# cslr_mcbsp register map
Vendor: Texas Instruments
Peripheral module from a debugger description file (folder TCI6484_C6457).
Registers are 32-bit, read-write, reset 0x0 unless marked. A register's access mark holds for its fields unless they carry their own. Offsets are as the file gives them; lines under a group give offsets from that group; [hi:lo] are bit positions; {n}, {i} and the like mark numbered series; 'fields as' and 'values as' point back to an identical list; <NAME> marks a mode.

## MCBSP
0x00 DRR ro — Data Receive Register
  [31:0] DR — Receive data
0x04 DXR ro — Data Transmit Register
  [31:0] DX — Transmit data
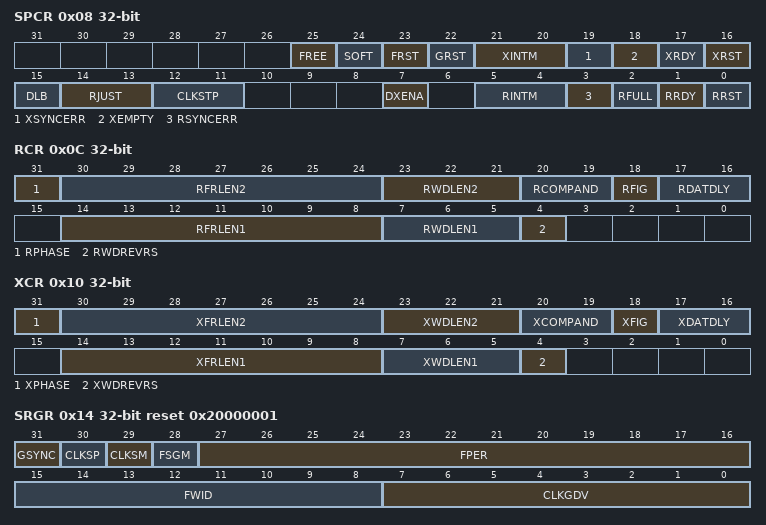
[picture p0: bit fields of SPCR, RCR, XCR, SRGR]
0x08 SPCR access not given — Serial Port Control Register
  [25] FREE rw — McBSP emulation mode bit (free mode)
    0=DISABLE; 1=ENABLE
  [24] SOFT rw — McBSP emulation mode bit (soft mode)
    0=DISABLE; 1=ENABLE
  [23] FRST rw — Frame-sync logic reset bit (negative polarity)
    0=RESET; 1=LOAD
  [22] GRST rw — Sample rate generator reset bit (negative polarity)
    0=RESET; 1=OUT_RST
  [21:20] XINTM rw — Transmit interrupt mode bits
  [19] XSYNCERR rw — Transmit frame-sync error bit (Caution: if XINTM = 11b, writing a 1 to XSYNCERR triggers a transmit interrupt just as if a transmit frame-sync error occurred)
    0=NO_ERR; 1=ERR
  [18] XEMPTY ro — Transmitter empty bit (negative polarity)
    0=EMPTY; 1=NOTEMPTY
  [17] XRDY ro — Transmitter ready bit
    0=NOTREADY; 1=READY
  [16] XRST rw — Transmitter reset bit (negative polarity)
    0=DISABLE; 1=ENABLE
  [15] DLB rw — Digital loopback mode bit
    0=DISABLE; 1=ENABLE
  [14:13] RJUST rw — Receive sign-extension and justification mode bits
  [12:11] CLKSTP rw — Clock stop mode bits
  [7] DXENA rw — DX delay enabler mode bit
    0=OFF; 1=ON
  [5:4] RINTM rw — Receive interrupt mode bits
  [3] RSYNCERR rw — Receive frame-sync error bit (Caution: If RINTM = 11b, writing a 1 to RSYNCERR triggers a receive interrupt just as if a receive frame-sync error occurred)
    0=NO_ERR; 1=ERR
  [2] RFULL ro — Receiver full bit
    0=NOT_FULL; 1=FULL
  [1] RRDY ro — Receiver ready bit
    0=NOTREADY; 1=READY
  [0] RRST rw — Receiver reset bit (negative polarity)
    0=DISABLE; 1=ENABLE
0x0C RCR access not given — Receive Control Register
  [31] RPHASE rw — Receive phase number bit
    0=SINGLEPHASE; 1=DUALPHASE
  [30:24] RFRLEN2 rw — Receive frame length 2
  [23:21] RWDLEN2 rw — Receive word length 2. Word length 11x b Reserved
  [20:19] RCOMPAND rw — Receive companding mode bits
  [18] RFIG rw — Receive frame-sync ignore bit
    0=RESTART; 1=IGNORE
  [17:16] RDATDLY rw — Receive data delay bits
  [14:8] RFRLEN1 rw — Receive frame length 1
  [7:5] RWDLEN1 rw — Receive word length 1.Word length 11x b Reserved
  [4] RWDREVRS rw — Receive 32-bit reversal feature 0: 32-bit reversal disabled 1: 32-bit reversal enabled. 32-bit data is received LSB first. RWDLEN should be set for 32-bit operation; else operation is undefined
    0=DISABLE; 1=ENABLE
0x10 XCR access not given — Transmit Control Register
  [31] XPHASE rw — Transmit phase number bit
    0=SINGLEPHASE; 1=DUALPHASE
  [30:24] XFRLEN2 rw — Transmit frame length 2
  [23:21] XWDLEN2 rw — Transmit word length 2. Word length 11x b Reserved
  [20:19] XCOMPAND rw — Transmit companding mode bits
  [18] XFIG rw — Transmit frame-sync ignore bit
    0=RESTART; 1=IGNORE
  [17:16] XDATDLY rw — Transmit data delay bits
    0=0_BIT; 1=1_BIT; 2=2_BIT
  [14:8] XFRLEN1 rw — Transmit frame length 1
  [7:5] XWDLEN1 rw — Transmit word length 1.Word length 11x b Reserved
  [4] XWDREVRS rw — Transmit 32-bit reversal feature 0: 32-bit reversal disabled 1: 32-bit reversal enabled. 32-bit data is transmitted LSB first. RWDLEN should be set for 32-bit operation; else operation is undefined
    0=DISABLE; 1=ENABLE
0x14 SRGR reset 0x20000001 — Sample Rate Generator Register
  [31] GSYNC — Clock synchronization mode bit for CLKG
    0=FREE_RUNNING; 1=RUNNING
  [30] CLKSP — CLKS pin polarity bit
    0=RISING; 1=FALLING
  [29] CLKSM — Sample rate generator input clock mode bit
    0=CLKS_PIN; 1=CPU_CLK
  [28] FSGM — Sample rate generator transmit frame-sync mode bit
    0=DXR_XSR; 1=FSG
  [27:16] FPER — Frame-sync period bits for FSG
  [15:8] FWID — Frame-sync pulse width bits for FSG
  [7:0] CLKGDV — Divide-down value for CLKG
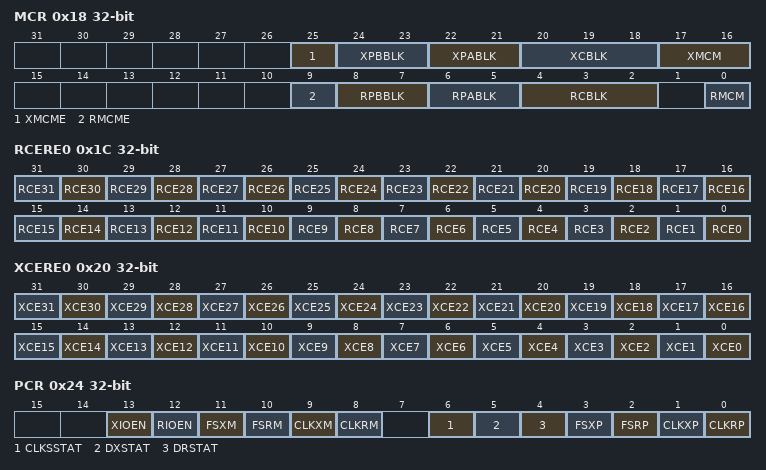
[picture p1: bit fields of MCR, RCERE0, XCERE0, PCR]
0x18 MCR access not given — Multichannel Control Register
  [25] XMCME rw — Transmit multichannel partition mode bit. XMCME operates in conjunction with RMCME. The RMCME and XMCME bit values need to be the same. RMCME XMCME Operation Mode 0 0 32 channel normal operation mode 1 1 128 channel normal operation mode 0 1 Reserved 1 0 Reserved
    0=32_CHANNEL (Normal 32-channel selection is enabled.); 1=128_CHANNEL (Six additional registers (XCER1-XCER3) are used to enable 128-channel selection.)
  [24:23] XPBBLK rw — Transmit partition B block bits
    0=SUBFRM_1; 1=SUBFRM_3; 2=SUBFRM_5; 3=SUBFRM_7
  [22:21] XPABLK rw — Transmit partition A block bits
    0=SUBFRM_0; 1=SUBFRM_2; 2=SUBFRM_4; 3=SUBFRM_6
  [20:18] XCBLK ro — Transmit current block indicator
    {v}=SUBFRM_{v} (v=0..7)
  [17:16] XMCM rw — Transmit multichannel selection mode bits
    0=ENABLE (All Transmitter Channels are enabled); 1=DISABLE (All Transmitter Channels are disabled); 2=ENABLE_MASK (All Transmitter Channels are enabled and masked); 3=SYMMETRIC (Symmetric transmission and reception)
  [9] RMCME rw — Receive multichannel partition mode bit. RMCME operates in conjunction with XMCME. The RMCME and XMCME bit values need to be the same. RMCME XMCME Operation Mode 0 0 32 channel normal operation mode 1 1 128 channel normal operation mode 0 1 Reserved 1 0 Reserved
    0=32_CHANNEL (Normal 32-channel selection is enabled.); 1=128_CHANNEL (Six additional registers (RCER1-RCER3) are used to enable 128-channel selection.)
  [8:7] RPBBLK rw — Receive partition B block bits
    0=SUBFRM_1; 1=SUBFRM_3; 2=SUBFRM_5; 3=SUBFRM_7
  [6:5] RPABLK rw — Receive partition A block bits
    0=SUBFRM_0; 1=SUBFRM_2; 2=SUBFRM_4; 3=SUBFRM_6
  [4:2] RCBLK ro — Receive current block indicator
    {v}=SUBFRM_{v} (v=0..7)
  [0] RMCM rw — Receive multichannel selection mode bit
    0=ENABLE (All Receiver Channels are enabled); 1=DISABLE (All Receiver Channels are disabled)
0x1C RCERE0 — Receive Channel Enable Register for Partition A and B
  [n] RCE{n} (n=16..31) — This bit used when RMCME = 1 and XMCME = 1: 0 - Disable reception on channel {n} 1 - Enable reception on channel {n} in partition B
  [n] RCE{n} (n=0..15) — This bit used when RMCME = 1 and XMCME = 1: 0 - Disable reception on channel {n} 1 - Enable reception on channel {n} in partition A
0x20 XCERE0 — Transmit Channel Enable Register for Partition A and B
  [n] XCE{n} (n=16..31) — This bit used when RMCME = 1 and XMCME = 1: 0 - Disable transmission on channel {n} 1 - Enable transmission on channel {n} in partition B
  [n] XCE{n} (n=0..15) — This bit used when RMCME = 1 and XMCME = 1: 0 - Disable transmission on channel {n} 1 - Enable transmission on channel {n} in partition A
0x24 PCR access not given — Pin Control Register
  [13] XIOEN rw — Transmit I/O enable bit
    0=NON_GPIO; 1=GPIO
  [12] RIOEN rw — Receive I/O enable bit
    0=NON_GPIO; 1=GPIO
  [11] FSXM rw — Transmit frame-sync mode bit
    0=INPUT (Select FSX as Input Pin); 1=OUTPUT (Select FSX as Output Pin)
  [10] FSRM rw — Receive frame-sync mode bit
    0=INPUT (Select FSR as Input Pin); 1=OUTPUT (Select FSR as Output Pin)
  [9] CLKXM rw — Transmit clock mode bit
    0=INPUT (Select CLKX as Input Pin); 1=OUTPUT (Select CLKX as Output Pin)
  [8] CLKRM rw — Receive clock mode bit
    0=INPUT (Select CLKR as Input Pin); 1=OUTPUT (Select CLKR as Output Pin)
  [6] CLKSSTAT ro — CLKS pin status bit
    0=LOW; 1=HIGH
  [5] DXSTAT rw — DX pin status bit
    0=LOW; 1=HIGH
  [4] DRSTAT ro — DR pin status bit
    0=LOW; 1=HIGH
  [3] FSXP rw — Transmit frame-sync polarity bit
    0=HIGH; 1=LOW
  [2] FSRP rw — Receive frame-sync polarity bit
    0=HIGH; 1=LOW
  [1] CLKXP rw — Transmit clock polarity bit
    0=RISING; 1=FALLING
  [0] CLKRP rw — Receive clock polarity bit
    0=FALLING; 1=RISING
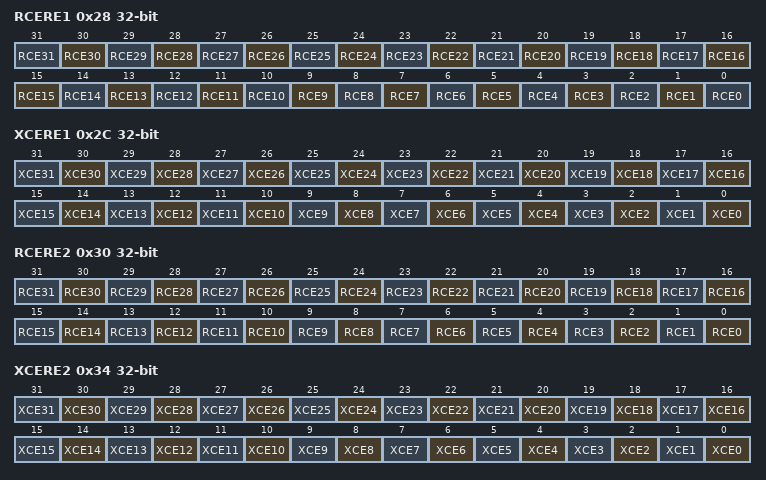
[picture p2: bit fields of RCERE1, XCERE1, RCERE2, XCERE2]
0x28 RCERE1 — Receive Channel Enable Register for Partition C and D
  [n] RCE{n} (n=16..31) — This bit used when RMCME = 1 and XMCME = 1: 0 - Disable reception on channel {n+32} 1 - Enable reception on channel {n+32} in partition D
  [n] RCE{n} (n=3..15) — This bit used when RMCME = 1 and XMCME = 1: 0 - Disable reception on channel {n+32} 1 - Enable reception on channel {n+32} in partition C
  [2] RCE2 — This bit used when RMCME = 1 and XMCME = 1: 0 - Disable reception on channel 34 1 - Enable reception on channel 34in partition C
  [1] RCE1 — This bit used when RMCME = 1 and XMCME = 1: 0 - Disable reception on channel 33 1 - Enable reception on channel 33 in partition C
  [0] RCE0 — This bit used when RMCME = 1 and XMCME = 1: 0 - Disable reception on channel 32 1 - Enable reception on channel 32 in partition C
0x2C XCERE1 — Transmit Channel Enable Register for Partition C and D
  [n] XCE{n} (n=16..31) — This bit used when RMCME = 1 and XMCME = 1: 0 - Disable transmission on channel {n+32} 1 - Enable transmission on channel {n+32} in partition D
  [n] XCE{n} (n=0..15) — This bit used when RMCME = 1 and XMCME = 1: 0 - Disable transmission on channel {n+32} 1 - Enable transmission on channel {n+32} in partition C
0x30 RCERE2 — Receive Channel Enable Register for Partition E and F
  [n] RCE{n} (n=16..31) — This bit used when RMCME = 1 and XMCME = 1: 0 - Disable reception on channel {n+64} 1 - Enable reception on channel {n+64} in partition F
  [n] RCE{n} (n=0..15) — This bit used when RMCME = 1 and XMCME = 1: 0 - Disable reception on channel {n+64} 1 - Enable reception on channel {n+64} in partition E
0x34 XCERE2 — Transmit Channel Enable Register for Partition E and F
  [n] XCE{n} (n=16..31) — This bit used when RMCME = 1 and XMCME = 1: 0 - Disable transmission on channel {n+64} 1 - Enable transmission on channel {n+64} in partition F
  [n] XCE{n} (n=0..15) — This bit used when RMCME = 1 and XMCME = 1: 0 - Disable transmission on channel {n+64} 1 - Enable transmission on channel {n+64} in partition E
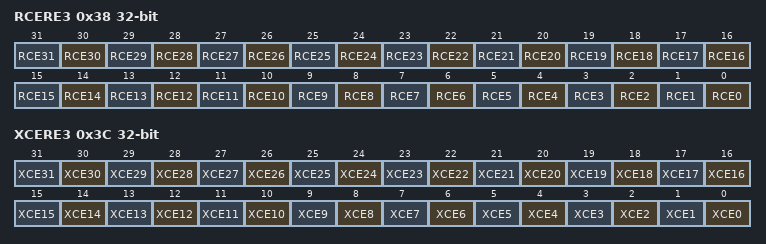
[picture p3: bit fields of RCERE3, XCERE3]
0x38 RCERE3 — Receive Channel Enable Register for Partition G and H
  [n] RCE{n} (n=16..31) — This bit used when RMCME = 1 and XMCME = 1: 0 - Disable reception on channel {n+96} 1 - Enable reception on channel {n+96} in partition H
  [n] RCE{n} (n=0..15) — This bit used when RMCME = 1 and XMCME = 1: 0 - Disable reception on channel {n+96} 1 - Enable reception on channel {n+96} in partition G
0x3C XCERE3 — Transmit Channel Enable Register for Partition G and H
  [n] XCE{n} (n=16..31) — This bit used when RMCME = 1 and XMCME = 1: 0 - Disable transmission on channel {n+96} 1 - Enable transmission on channel {n+96} in partition H
  [n] XCE{n} (n=0..15) — This bit used when RMCME = 1 and XMCME = 1: 0 - Disable transmission on channel {n+96} 1 - Enable transmission on channel {n+96} in partition G
